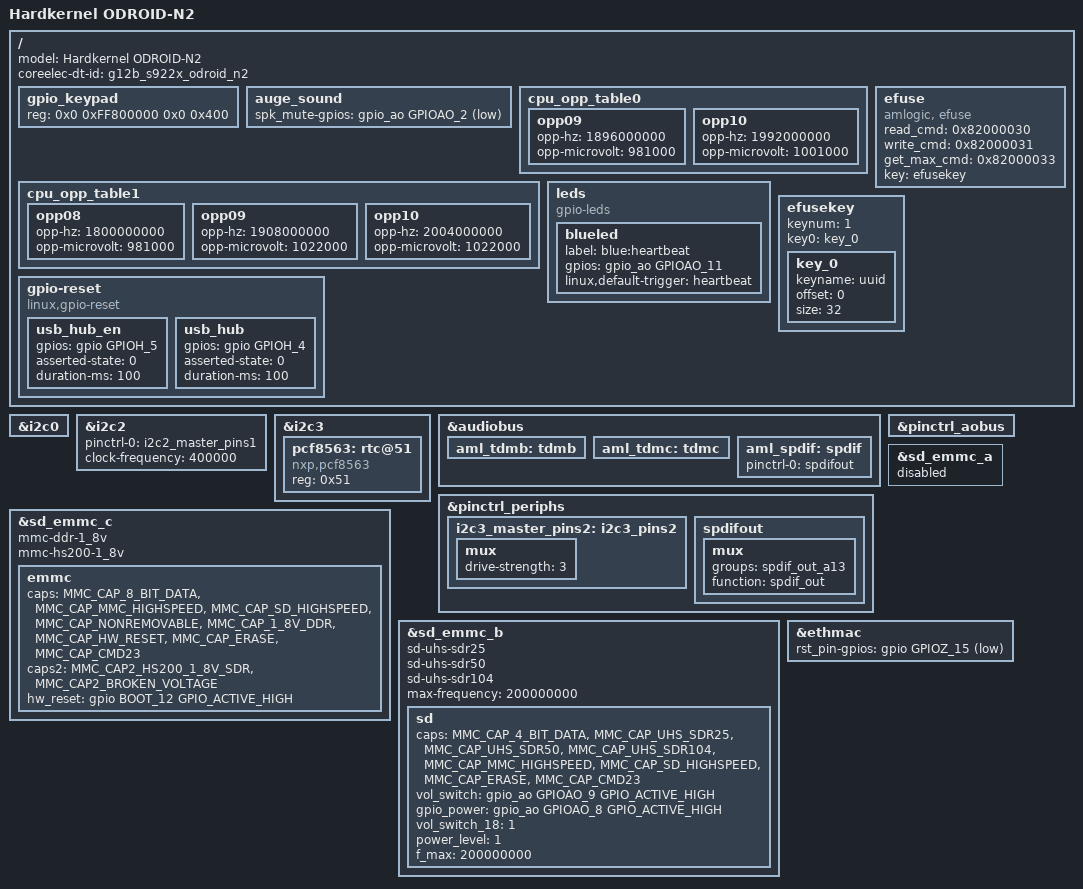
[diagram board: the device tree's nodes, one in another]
#include "coreelec_g12b_a.dtsi"

/{
	model = "Hardkernel ODROID-N2";
	/delete-property/ amlogic-dt-id;
	coreelec-dt-id = "g12b_s922x_odroid_n2";

	/delete-node/ memory@00000000;
	/delete-node/ gpioleds;
	/delete-node/ bt-dev;
	/delete-node/ wifi;
	/delete-node/ wifi_pwm_conf;
	/delete-node/ adc_keypad;
	/delete-node/ unifykey;
	/delete-node/ rtc;

	gpio_keypad {
		/delete-property/ key-gpios;
		/delete-property/ detect_mode;
		reg = <0x0 0xFF800000 0x0 0x400>;
	};

	auge_sound {
		spk_mute-gpios = <&gpio_ao GPIOAO_2 GPIO_ACTIVE_LOW>;
	};

	cpu_opp_table0: cpu_opp_table0 {
		opp09 {
			opp-hz = /bits/ 64 <1896000000>;
			opp-microvolt = <981000>;
		};
		opp10 {
			opp-hz = /bits/ 64 <1992000000>;
			opp-microvolt = <1001000>;
		};
	};

	cpu_opp_table1: cpu_opp_table1 {
		opp08 {
			opp-hz = /bits/ 64 <1800000000>;
			opp-microvolt = <981000>;
		};
		opp09 {
			opp-hz = /bits/ 64 <1908000000>;
			opp-microvolt = <1022000>;
		};
		opp10 {
			opp-hz = /bits/ 64 <2004000000>;
			opp-microvolt = <1022000>;
		};
	};

	leds {
		compatible = "gpio-leds";
		blueled {
			label = "blue:heartbeat";
			gpios = <&gpio_ao GPIOAO_11 GPIO_ACTIVE_HIGH>;
			linux,default-trigger = "heartbeat";
		};
	};

	gpio-reset {
		compatible = "linux,gpio-reset";
		usb_hub_en {
			gpios = <&gpio GPIOH_5 GPIO_ACTIVE_HIGH>;
			asserted-state = <0>;
			duration-ms = <100>;
		};
		usb_hub {
			gpios = <&gpio GPIOH_4 GPIO_ACTIVE_HIGH>;
			asserted-state = <0>;
			duration-ms = <100>;
		};
	};

	efuse: efuse {
		compatible = "amlogic, efuse";
		read_cmd = <0x82000030>;
		write_cmd = <0x82000031>;
		get_max_cmd = <0x82000033>;
		key = <&efusekey>;
		status = "okay";
	};

	efusekey: efusekey {
		keynum = <1>;
		key0 = <&key_0>;

		key_0: key_0 {
			keyname = "uuid";
			offset = <0>;
			size = <32>;
		};
	};
};

&i2c0 {
	/delete-property/ pinctrl-names;
	/delete-property/ pinctrl-0;
	/delete-property/ clock-frequency;
};

&i2c2 {
	status = "okay";
	pinctrl-0 = <&i2c2_master_pins1>;
	clock-frequency = <400000>;
};

&i2c3 {
	pcf8563: rtc@51 {
		compatible = "nxp,pcf8563";
		reg = <0x51>;
	};
};

&audiobus {
	/delete-node/ tdma;

	aml_tdmb: tdmb {
		/delete-property/ pinctrl-names;
		/delete-property/ pinctrl-0;
	};

	aml_tdmc: tdmc {
		/delete-property/ pinctrl-names;
		/delete-property/ pinctrl-0;
	};

	aml_spdif: spdif {
		pinctrl-names = "spdif_pins";
		pinctrl-0 = <&spdifout>;
		/delete-property/ pinctrl-1;
	};
};

&pinctrl_periphs {
	i2c3_master_pins2: i2c3_pins2 {
		mux {
			drive-strength = <3>;
		};
	};

	spdifout: spdifout {
		mux {/* GPIOA_13 */
			groups = "spdif_out_a13";
			function = "spdif_out";
		};
	};
};

&pinctrl_aobus {
	/delete-node/ spdifout;
	/delete-node/ spdifout_a_mute;
};

&sd_emmc_c {
	mmc-ddr-1_8v;
	mmc-hs200-1_8v;
	emmc {
		caps = "MMC_CAP_8_BIT_DATA",
			 "MMC_CAP_MMC_HIGHSPEED",
			 "MMC_CAP_SD_HIGHSPEED",
			 "MMC_CAP_NONREMOVABLE",
			 "MMC_CAP_1_8V_DDR",
			 "MMC_CAP_HW_RESET",
			 "MMC_CAP_ERASE",
			 "MMC_CAP_CMD23";
		caps2 = "MMC_CAP2_HS200_1_8V_SDR",
			"MMC_CAP2_BROKEN_VOLTAGE";
		hw_reset = <&gpio BOOT_12 GPIO_ACTIVE_HIGH>;
	};
};

&sd_emmc_b {
	sd-uhs-sdr25;
	sd-uhs-sdr50;
	sd-uhs-sdr104;
	max-frequency = <200000000>;
	sd {
		caps = "MMC_CAP_4_BIT_DATA",
			 "MMC_CAP_UHS_SDR25",
			 "MMC_CAP_UHS_SDR50",
			 "MMC_CAP_UHS_SDR104",
			 "MMC_CAP_MMC_HIGHSPEED",
			 "MMC_CAP_SD_HIGHSPEED",
			 "MMC_CAP_ERASE",
			 "MMC_CAP_CMD23";
		vol_switch = <&gpio_ao GPIOAO_9 GPIO_ACTIVE_HIGH>;
		gpio_power = <&gpio_ao GPIOAO_8 GPIO_ACTIVE_HIGH>;
		vol_switch_18 = <1>;
		power_level = <1>;
		f_max = <200000000>;
	};
};

&sd_emmc_a {
	status = "disabled";
	/delete-node/ sdio;
};

&ethmac {
	rst_pin-gpios = <&gpio GPIOZ_15 GPIO_ACTIVE_LOW>;
};
